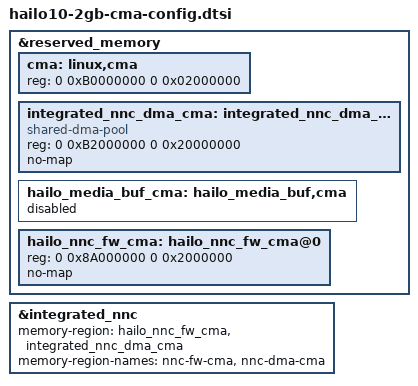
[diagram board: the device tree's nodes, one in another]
// SPDX-License-Identifier:     GPL-2.0
/*
 * Copyright (c) 2019-2025 Hailo Technologies Ltd. All rights reserved.
 */

&reserved_memory {
    // Override linux CMA - decrease it to 32MiB and move (no media library)
    cma: linux,cma {
        reg = <0 0xB0000000 0 0x02000000>;
    };

    // Reserve memory only for integrated nnc dma.
    integrated_nnc_dma_cma: integrated_nnc_dma_cma,cma {
        compatible = "shared-dma-pool";
        reg = <0 0xB2000000 0 0x20000000>;
        no-map;
    };

    hailo_media_buf_cma: hailo_media_buf,cma {
        status = "disabled";
    };

    /* Hailo nn-core firmware: static reserve 32MiB area: [0x8e000000 - 0x90000000)
        - must be at 0x8XXXXXXX for main2fast LUT to work (accessing 0x3XXXXXXX->0x8XXXXXXX in the NNM firmware) */
    hailo_nnc_fw_cma: hailo_nnc_fw_cma@0 {
        /* Moved from 0x8e000000 to 0x8A000000 */
        reg = <0 0x8A000000 0 0x2000000>;
        no-map;
    };
};

&integrated_nnc {
    memory-region = <&hailo_nnc_fw_cma>, <&integrated_nnc_dma_cma>;
    memory-region-names = "nnc-fw-cma", "nnc-dma-cma";
};
